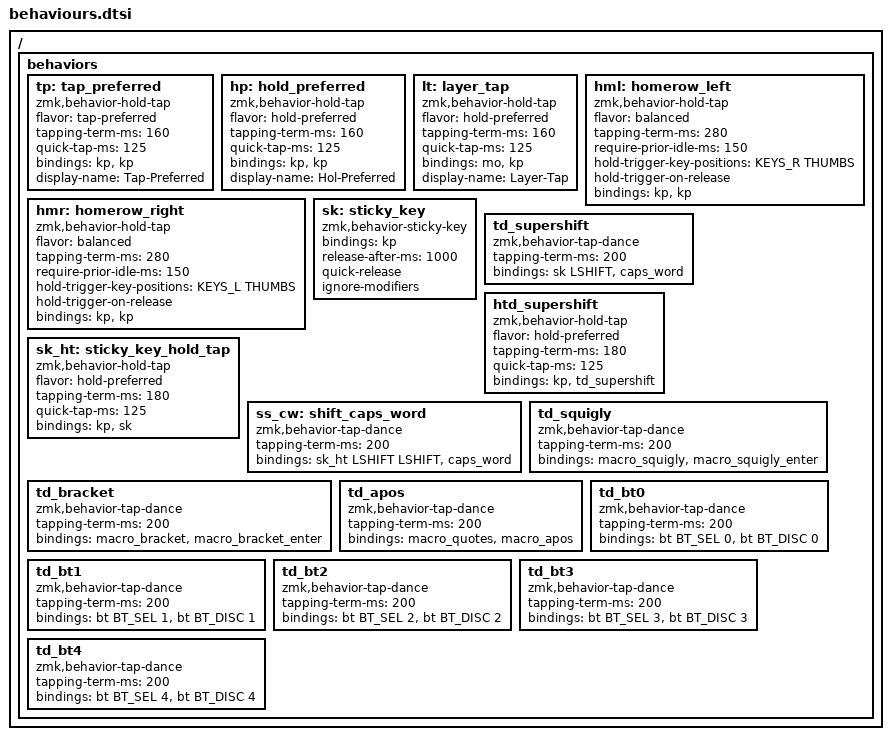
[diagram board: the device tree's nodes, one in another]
/ {
  behaviors {
    tp: tap_preferred {
      compatible = "zmk,behavior-hold-tap";
      #binding-cells = <2>;
      flavor = "tap-preferred";
      tapping-term-ms = <160>;
      quick-tap-ms = <125>;
      //require-prior-idle-ms = <130>;
      bindings = <&kp>, <&kp>;
      display-name = "Tap-Preferred";
    };
    hp: hold_preferred {
      compatible = "zmk,behavior-hold-tap";
      #binding-cells = <2>;
      flavor = "hold-preferred";
      tapping-term-ms = <160>;
      quick-tap-ms = <125>;
      //require-prior-idle-ms = <130>;
      bindings = <&kp>, <&kp>;
      display-name = "Hol-Preferred";
    };
    lt: layer_tap {
      compatible = "zmk,behavior-hold-tap";
      #binding-cells = <2>;
      flavor = "hold-preferred";
      tapping-term-ms = <160>;
      quick-tap-ms = <125>;
      //require-prior-idle-ms = <130>;
      bindings = <&mo>, <&kp>;
      display-name = "Layer-Tap";
    };
    hml: homerow_left {
      compatible = "zmk,behavior-hold-tap";
      #binding-cells = <2>;
      flavor = "balanced";
      tapping-term-ms = <280>;
      require-prior-idle-ms = <150>;
      hold-trigger-key-positions = <KEYS_R THUMBS>;
      hold-trigger-on-release;
      bindings = <&kp>, <&kp>;
    };
    hmr: homerow_right {
      compatible = "zmk,behavior-hold-tap";
      #binding-cells = <2>;
      flavor = "balanced";
      tapping-term-ms = <280>;
      require-prior-idle-ms = <150>;
      hold-trigger-key-positions = <KEYS_L THUMBS>;
      hold-trigger-on-release;
      bindings = <&kp>, <&kp>;
    };
    sk: sticky_key {
      compatible = "zmk,behavior-sticky-key";
      #binding-cells = <1>;
      bindings = <&kp>;
      release-after-ms = <1000>;
      quick-release;
      ignore-modifiers;
    };
    td_supershift: td_supershift {
      compatible = "zmk,behavior-tap-dance";
      #binding-cells = <0>;
      tapping-term-ms = <200>;
      bindings = <&sk LSHIFT>, <&caps_word>;
    };
    htd_supershift: htd_supershift {
      compatible = "zmk,behavior-hold-tap";
      #binding-cells = <2>;
      flavor = "hold-preferred";
      tapping-term-ms = <180>;
      quick-tap-ms = <125>;
      bindings = <&kp>, <&td_supershift>;
    };
    sk_ht: sticky_key_hold_tap {
      compatible = "zmk,behavior-hold-tap";
      #binding-cells = <2>;
      flavor = "hold-preferred";
      tapping-term-ms = <180>;
      quick-tap-ms = <125>;
      bindings = <&kp>, <&sk>;
    };
    ss_cw: shift_caps_word {
      compatible = "zmk,behavior-tap-dance";
      #binding-cells = <0>;
      tapping-term-ms = <200>;
      bindings = <&sk_ht LSHIFT LSHIFT>, <&caps_word>;
    };
    td_squigly: td_squigly {
      compatible = "zmk,behavior-tap-dance";
      #binding-cells = <0>;
      tapping-term-ms = <200>;
      bindings = <&macro_squigly>, <&macro_squigly_enter>;
    };
    td_bracket: td_bracket {
      compatible = "zmk,behavior-tap-dance";
      #binding-cells = <0>;
      tapping-term-ms = <200>;
      bindings = <&macro_bracket>, <&macro_bracket_enter>;
    };
    td_apos: td_apos {
      compatible = "zmk,behavior-tap-dance";
      #binding-cells = <0>;
      tapping-term-ms = <200>;
      bindings = <&macro_quotes>, <&macro_apos>;
    };
    td_bt0: td_bt0 {
      compatible = "zmk,behavior-tap-dance";
      #binding-cells = <0>;
      tapping-term-ms = <200>;
      bindings = <&bt BT_SEL 0>, <&bt BT_DISC 0>;
    };
    td_bt1: td_bt1 {
      compatible = "zmk,behavior-tap-dance";
      #binding-cells = <0>;
      tapping-term-ms = <200>;
      bindings = <&bt BT_SEL 1>, <&bt BT_DISC 1>;
    };
    td_bt2: td_bt2 {
      compatible = "zmk,behavior-tap-dance";
      #binding-cells = <0>;
      tapping-term-ms = <200>;
      bindings = <&bt BT_SEL 2>, <&bt BT_DISC 2>;
    };
    td_bt3: td_bt3 {
      compatible = "zmk,behavior-tap-dance";
      #binding-cells = <0>;
      tapping-term-ms = <200>;
      bindings = <&bt BT_SEL 3>, <&bt BT_DISC 3>;
    };
    td_bt4: td_bt4 {
      compatible = "zmk,behavior-tap-dance";
      #binding-cells = <0>;
      tapping-term-ms = <200>;
      bindings = <&bt BT_SEL 4>, <&bt BT_DISC 4>;
    };
  };
};
